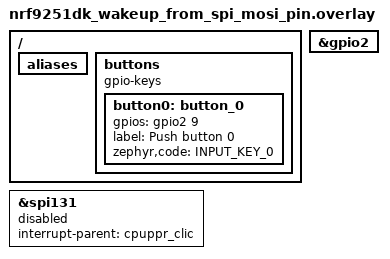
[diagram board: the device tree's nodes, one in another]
/*
 * Copyright (c) 2026 Nordic Semiconductor ASA
 *
 * SPDX-License-Identifier: LicenseRef-Nordic-5-Clause
 */

/* Delete LED3 on P2.09 as that GPIO is used as a button0. */
/ {
	aliases {
		/delete-property/ led3;
	};
};

/delete-node/ &led3;

/ {
	/*
	 * Redefine sw0/button0 to use P2.03 (SPI MOSI) to P2.09 (button0) loopback.
	 * Thus, when "remote" starts SPI transfer, there will be gpio interrupt,
	 * the same as originally triggered by sw0 button.
	 * P2.03 - P2.09 loopback is needed.
	 */
	buttons {
		compatible = "gpio-keys";

		button0: button_0 {
			gpios = <&gpio2 9 (GPIO_PULL_DOWN | GPIO_ACTIVE_HIGH)>;
			label = "Push button 0";
			zephyr,code = <INPUT_KEY_0>;
		};
	};
};

&spi131 {
	status = "reserved";
	interrupt-parent = <&cpuppr_clic>;
};

&gpio2 {
	status = "okay";
};
